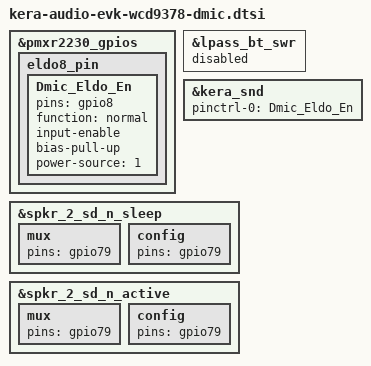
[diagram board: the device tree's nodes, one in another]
// SPDX-License-Identifier: BSD-3-Clause
/*
 * Copyright (c) Qualcomm Technologies, Inc. and/or its subsidiaries.
 */

/dts-v1/;
/plugin/;

#include "kera-iot-audio-cdp.dtsi"

&pmxr2230_gpios {
	eldo8_pin {
		Dmic_Eldo_En: Dmic_Eldo_En {
			pins = "gpio8";
			function = "normal";
			input-enable;
			bias-pull-up;
			power-source = <1>;
		};
	};
};

&lpass_bt_swr {
	status = "disabled";
};

&kera_snd {
	pinctrl-names = "default";
	pinctrl-0 = <&Dmic_Eldo_En>;
};

&spkr_2_sd_n_sleep {
	mux {
		pins = "gpio79";
	};

	config {
		pins = "gpio79";
	};
};

&spkr_2_sd_n_active {
	mux {
		pins = "gpio79";
	};

	config {
		pins = "gpio79";
	};
};
